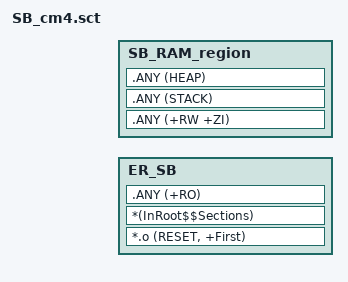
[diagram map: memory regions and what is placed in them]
#! armclang --target=arm-arm-none-eabi  -mcpu=cortex-m0plus -E -xc
; *************************************************************
; *** Scatter-Loading Description File generated by uVision ***
; *************************************************************
#include "..\..\Linker_Common\MDK-ARM\mapping_sbsfu.h"
#include "..\..\Linker_Common\MDK-ARM\mapping_fwimg.h"

; *** regions needed by SBSFU project ***
LR_SB M4_SB_REGION_ROM_START M4_SB_ROM_REGION_SIZE {  
  ER_SB M4_SB_REGION_ROM_START M4_SB_ROM_REGION_SIZE {
   *.o (RESET, +First)
  *(InRoot$$Sections)
  .ANY (+RO)
  }
  SB_RAM_region M4_SB_REGION_RAM_START M4_SB_RAM_REGION_SIZE  {
  .ANY (+RW +ZI)
  .ANY (STACK)
  .ANY (HEAP)
  }
}

